# CH569 register map
Vendor: WCH Ltd.; File version: 1.1
Registers are 32-bit, read-write, reset 0x0 unless marked. A register's access mark holds for its fields unless they carry their own. Offsets are from the block's base; [hi:lo] are bit positions; 'fields as' and 'values as' point back to an identical list.

## SPI0
Base 0x40004000
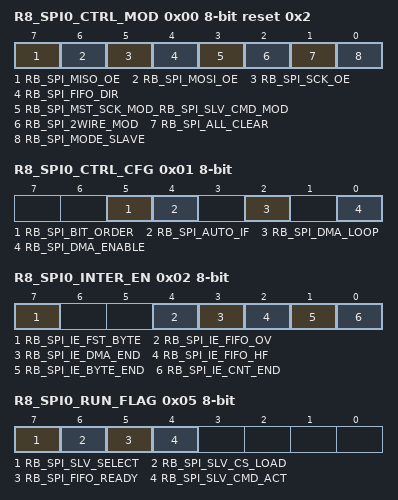
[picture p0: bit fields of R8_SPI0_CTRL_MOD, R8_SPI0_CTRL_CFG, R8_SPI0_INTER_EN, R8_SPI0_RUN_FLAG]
0x00 R8_SPI0_CTRL_MOD 8-bit reset 0x2 — SPI0 mode control
  [7] RB_SPI_MISO_OE — SPI MISO output enable
  [6] RB_SPI_MOSI_OE — SPI MOSI output enable
  [5] RB_SPI_SCK_OE — SPI SCK output enable
  [4] RB_SPI_FIFO_DIR — SPI FIFO direction
  [3] RB_SPI_MST_SCK_MOD_RB_SPI_SLV_CMD_MOD — SPI master clock mode _ SPI slave command mode
  [2] RB_SPI_2WIRE_MOD — SPI enable 2 wire mode
  [1] RB_SPI_ALL_CLEAR — force clear SPI FIFO and count
  [0] RB_SPI_MODE_SLAVE — SPI slave mode
0x01 R8_SPI0_CTRL_CFG 8-bit — SPI0 configuration control
  [5] RB_SPI_BIT_ORDER — SPI bit data order
  [4] RB_SPI_AUTO_IF — enable buffer/FIFO accessing to auto clear RB_SPI_IF_BYTE_END interrupt flag
  [2] RB_SPI_DMA_LOOP — SPI DMA address loop enable
  [0] RB_SPI_DMA_ENABLE — SPI DMA enable
0x02 R8_SPI0_INTER_EN 8-bit — SPI0 interrupt enable
  [7] RB_SPI_IE_FST_BYTE — enable interrupt for SPI slave mode first byte received
  [4] RB_SPI_IE_FIFO_OV — enable interrupt for SPI FIFO overflow
  [3] RB_SPI_IE_DMA_END — enable interrupt for SPI DMA completion
  [2] RB_SPI_IE_FIFO_HF — enable interrupt for SPI FIFO half
  [1] RB_SPI_IE_BYTE_END — enable interrupt for SPI byte exchanged
  [0] RB_SPI_IE_CNT_END — enable interrupt for SPI total byte count end
0x03 R8_SPI0_CLOCK_DIV_R8_SPI0_SLAVE_PRE 8-bit reset 0x10 — SPI0 master clock divisor / SPI0 slave preset value
  [7:0] R8_SPI0_CLOCK_DIV_R8_SPI0_SLAVE_PRE — master clock divisor / SPI0 slave preset value
0x04 R8_SPI0_BUFFER 8-bit — SPI0 data buffer
  [7:0] R8_SPI0_BUFFER — SPI data buffer
0x05 R8_SPI0_RUN_FLAG 8-bit ro — SPI0 work flag
  [7] RB_SPI_SLV_SELECT — SPI slave selection status
  [6] RB_SPI_SLV_CS_LOAD — SPI slave chip-select loading status
  [5] RB_SPI_FIFO_READY — SPI FIFO ready status
  [4] RB_SPI_SLV_CMD_ACT — SPI slave command flag
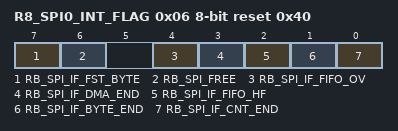
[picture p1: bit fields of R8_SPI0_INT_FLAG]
0x06 R8_SPI0_INT_FLAG 8-bit reset 0x40 — SPI0 interrupt flag
  [7] RB_SPI_IF_FST_BYTE — interrupt flag for SPI slave mode first byte received
  [6] RB_SPI_FREE — current SPI free status
  [4] RB_SPI_IF_FIFO_OV — interrupt flag for SPI FIFO overflow
  [3] RB_SPI_IF_DMA_END — interrupt flag for SPI DMA completion
  [2] RB_SPI_IF_FIFO_HF — interrupt flag for SPI FIFO half
  [1] RB_SPI_IF_BYTE_END — interrupt flag for SPI byte exchanged
  [0] RB_SPI_IF_CNT_END — interrupt flag for SPI total byte count end
0x07 R8_SPI0_FIFO_COUNT 8-bit — SPI0 FIFO count status
  [7:0] R8_SPI0_FIFO_COUNT — SPI FIFO count status
0x0C R16_SPI0_TOTAL_CNT 16-bit — SPI0 total byte count, only low 12 bit
  [15:0] R16_SPI0_TOTAL_CNT — SPI total byte count, only low 12 bit
0x10 R8_SPI0_FIFO 8-bit — SPI0 FIFO register
  [7:0] R8_SPI0_FIFO — SPI FIFO register
0x13 R8_SPI0_FIFO_COUNT1 8-bit — SPI0 FIFO count status
  [7:0] R8_SPI0_FIFO_COUNT1 — SPI FIFO count statu
0x14 R32_SPI0_DMA_NOW — SPI0 DMA current address
  [17:0] R16_SPI0_DMA_NOW — SPI DMA current address
0x18 R32_SPI0_DMA_BEG — SPI0 DMA begin address
  [17:0] R16_SPI0_DMA_BEG — SPI DMA begin address
0x1C R32_SPI0_DMA_END — SPI0 DMA end address
  [17:0] R16_SPI0_DMA_END — SPI DMA end address

## SPI1
Base 0x40004400
Registers as SPI0 (with SPI0 read as SPI1); these are added or differ:
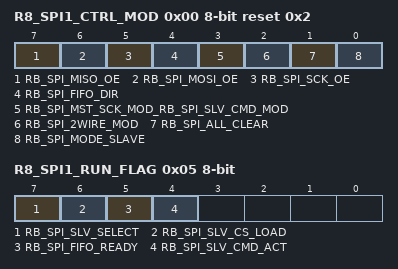
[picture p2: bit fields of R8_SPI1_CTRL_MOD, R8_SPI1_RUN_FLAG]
0x00 R8_SPI1_CTRL_MOD 8-bit reset 0x2 — SPI1 mode control
  [7] RB_SPI_MISO_OE — SPI MISO output enable
  [6] RB_SPI_MOSI_OE — SPI MOSI output enable
  [5] RB_SPI_SCK_OE — SPI SCK output enable
  [4] RB_SPI_FIFO_DIR — SPI FIFO direction
  [3] RB_SPI_MST_SCK_MOD_RB_SPI_SLV_CMD_MOD — SPI master clock mode / SPI slave command mode
  [2] RB_SPI_2WIRE_MOD — SPI enable 2 wire mode
  [1] RB_SPI_ALL_CLEAR — force clear SPI FIFO and count
  [0] RB_SPI_MODE_SLAVE — SPI slave mode
0x03 R8_SPI1_CLOCK_DIV_R8_SPI1_SLAVE_PRE 8-bit reset 0x10 — SPI1 master clock divisor / SPI0 slave preset value
  [7:0] R8_SPI1_CLOCK_DIV_R8_SPI1_SLAVE_PRESET — master clock divisor / SPI0 slave preset value
0x05 R8_SPI1_RUN_FLAG 8-bit — SPI1 work flag
  fields as SPI0.R8_SPI0_RUN_FLAG
0x13 R8_SPI1_FIFO_COUNT1 8-bit — SPI0 FIFO count status
  [7:0] R8_SPI1_FIFO_COUNT1 — SPI FIFO count statu
